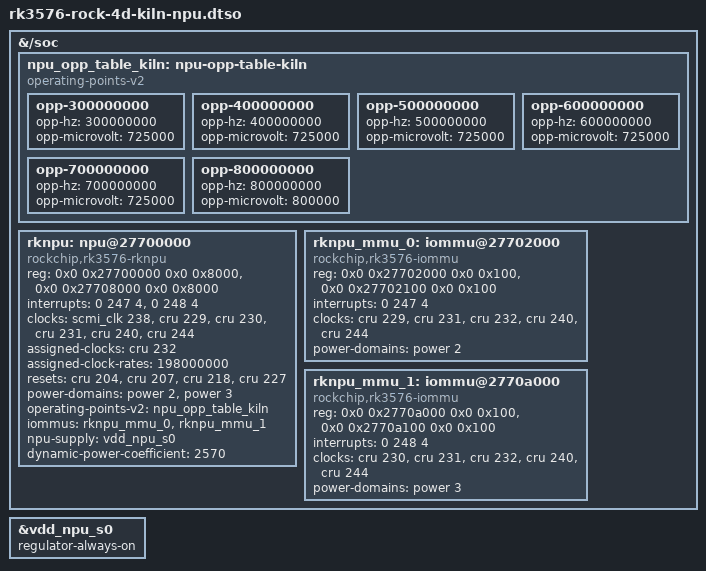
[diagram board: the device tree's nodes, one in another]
// SPDX-License-Identifier: (GPL-2.0-only OR MIT)
/*
 * Kiln NPU overlay for Radxa ROCK 4D (RK3576) on a mainline / Armbian kernel.
 *
 * Self-contained: adds the single vendor-shaped npu@27700000 plus its two v2
 * IOMMUs from scratch, for kernels (like Armbian edge) whose base DT has the NPU
 * SoC peripherals but NO driver-bindable NPU compute node. It references only
 * &cru, &power, &vdd_npu_s0 and &scmi_clk -- symbols present in the ROCK 4D base
 * DT -- and uses NUMERIC clock/reset/power IDs so it compiles with plain `dtc`,
 * no dt-bindings headers needed:
 *   clocks : ACLK_RKNN0=229 ACLK_RKNN1=230 HCLK_RKNN_ROOT=231 CLK_RKNN_DSU0=232
 *            PCLK_NPUTOP_ROOT=233 ACLK_RKNN_CBUF=240 HCLK_RKNN_CBUF=244
 *   resets : SRST_A_RKNN0=204 SRST_A_RKNN1=207 SRST_A_RKNN_CBUF=218 SRST_H_RKNN_CBUF=227
 *   power  : RK3576_PD_NPU0=2 RK3576_PD_NPU1=3    irq: GIC_SPI=0 LEVEL_HIGH=4
 *
 * clk_npu is the NPU DSU clock and is owned by BL31 firmware -- it MUST be taken
 * through &scmi_clk at the FIRMWARE SCMI index 238 (SCMI_CLK_RKNN_DSU0), not the
 * mainline CRU CLK_RKNN_DSU0=232. Referencing <&cru 232> for clk_npu drives a
 * plain CRU gate while the real DSU clock never comes up, so the NPU power domain
 * cannot stabilise and probe dies with "failed to get pm runtime ... -110". The
 * IOMMU nodes still use <&cru 232> for their DSU gate (that path only enables,
 * it does not set the rate). See kernel-patches/0004 for the in-tree NPU node.
 *
 * Build:  dtc -@ -I dts -O dtb -o rk3576-rock-4d-kiln-npu.dtbo rk3576-rock-4d-kiln-npu.dtso
 * (the standalone "reg has invalid length" / addr-size warnings are cosmetic --
 * reg is interpreted against the base /soc's #address/#size-cells at apply time.)
 */
/dts-v1/;
/plugin/;

&{/soc} {
	npu_opp_table_kiln: npu-opp-table-kiln {
		compatible = "operating-points-v2";
		opp-300000000 { opp-hz = /bits/ 64 <300000000>; opp-microvolt = <725000>; };
		opp-400000000 { opp-hz = /bits/ 64 <400000000>; opp-microvolt = <725000>; };
		opp-500000000 { opp-hz = /bits/ 64 <500000000>; opp-microvolt = <725000>; };
		opp-600000000 { opp-hz = /bits/ 64 <600000000>; opp-microvolt = <725000>; };
		opp-700000000 { opp-hz = /bits/ 64 <700000000>; opp-microvolt = <725000>; };
		opp-800000000 { opp-hz = /bits/ 64 <800000000>; opp-microvolt = <800000>; };
	};

	rknpu: npu@27700000 {
		compatible = "rockchip,rk3576-rknpu";
		reg = <0x0 0x27700000 0x0 0x8000>,
		      <0x0 0x27708000 0x0 0x8000>;
		interrupts = <0 247 4>, <0 248 4>;
		interrupt-names = "npu0_irq", "npu1_irq";
		clocks = <&scmi_clk 238>, <&cru 229>, <&cru 230>, <&cru 231>,
			 <&cru 240>, <&cru 244>;
		clock-names = "clk_npu", "aclk0", "aclk1", "hclk_root",
			      "aclk_cbuf", "hclk_cbuf";
		assigned-clocks = <&cru 232>;
		assigned-clock-rates = <198000000>;
		resets = <&cru 204>, <&cru 207>, <&cru 218>, <&cru 227>;
		reset-names = "srst_a0", "srst_a1", "srst_a_cbuf", "srst_h_cbuf";
		power-domains = <&power 2>, <&power 3>;
		power-domain-names = "npu0", "npu1";
		operating-points-v2 = <&npu_opp_table_kiln>;
		iommus = <&rknpu_mmu_0>, <&rknpu_mmu_1>;
		npu-supply = <&vdd_npu_s0>;
		#cooling-cells = <2>;
		dynamic-power-coefficient = <2570>;
		status = "okay";
	};

	rknpu_mmu_0: iommu@27702000 {
		compatible = "rockchip,rk3576-iommu", "rockchip,rk3568-iommu";
		reg = <0x0 0x27702000 0x0 0x100>,
		      <0x0 0x27702100 0x0 0x100>;
		interrupts = <0 247 4>;
		clocks = <&cru 229>, <&cru 231>, <&cru 232>, <&cru 240>, <&cru 244>;
		#iommu-cells = <0>;
		power-domains = <&power 2>;
		status = "okay";
	};

	rknpu_mmu_1: iommu@2770a000 {
		compatible = "rockchip,rk3576-iommu", "rockchip,rk3568-iommu";
		reg = <0x0 0x2770a000 0x0 0x100>,
		      <0x0 0x2770a100 0x0 0x100>;
		interrupts = <0 248 4>;
		clocks = <&cru 230>, <&cru 231>, <&cru 232>, <&cru 240>, <&cru 244>;
		#iommu-cells = <0>;
		power-domains = <&power 3>;
		status = "okay";
	};
};

/*
 * Keep the NPU rail powered. vdd_npu_s0 is only regulator-boot-on in the base
 * DT, so the regulator core disables it ~30 s into boot once the driver balances
 * its enable/disable; the genpd domain still reports "on", so the SECOND NPU
 * inference reads a register on a dead rail and wedges the board (works once,
 * then hangs). regulator-always-on holds the rail so every NPU use lands on a
 * live core. This is the overlay equivalent of kernel-patches/0010.
 */
&vdd_npu_s0 {
	regulator-always-on;
};
